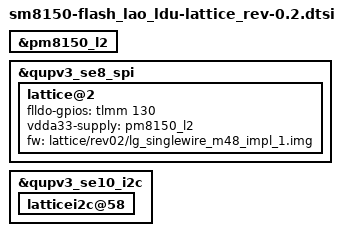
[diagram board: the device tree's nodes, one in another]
/*
 * Copyright (c) 2018, The Linux Foundation. All rights reserved.
 *
 * This program is free software; you can redistribute it and/or modify
 * it under the terms of the GNU General Public License version 2 and
 * only version 2 as published by the Free Software Foundation.
 *
 * This program is distributed in the hope that it will be useful,
 * but WITHOUT ANY WARRANTY; without even the implied warranty of
 * MERCHANTABILITY or FITNESS FOR A PARTICULAR PURPOSE.  See the
 * GNU General Public License for more details.
 */
&pm8150_l2 {
	status = "ok";
};

&qupv3_se8_spi {
	lattice@2 {
		flldo-gpios = <&tlmm 130 0>;
		vdda33-supply = <&pm8150_l2>;
		fw = "lattice/rev02/lg_singlewire_m48_impl_1.img";
		status = "ok";
	};
};

&qupv3_se10_i2c {
	status = "ok";
	latticei2c@58 {
		status = "ok";
	};
};
